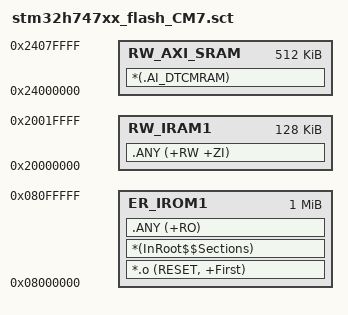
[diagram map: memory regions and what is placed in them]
; *************************************************************
; *** Scatter-Loading Description File generated by uVision ***
; *************************************************************

LR_IROM1 0x08000000 0x00100000  {    ; load region size_region
  ER_IROM1 0x08000000 0x00100000  {  ; load address = execution address
   *.o (RESET, +First)
   *(InRoot$$Sections)
   .ANY (+RO)
  }
  RW_IRAM1 0x20000000 0x00020000{  ; RW data (DTCMRAM 128KB)
   .ANY (+RW +ZI)
  }
  RW_AXI_SRAM 0x24000000 0x00080000{  ; AXI SRAM 512KB - AI activation buffers
   *(.AI_DTCMRAM)
  }
}
